# MSP430F5529 register map
Vendor: msp430gen; File version: VERGEN_IDEMPOTENT_OUTPUT
Registers are 8-bit, read-write, reset 0x0 unless marked. A register's access mark holds for its fields unless they carry their own. Offsets are from the block's base; [hi:lo] are bit positions; {n}, {i} and the like mark numbered series.

## USCI_A0_SPI_MODE
Base 0x000005C0
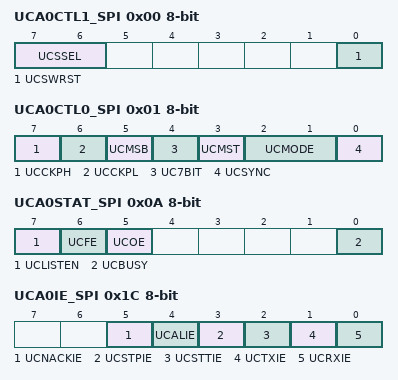
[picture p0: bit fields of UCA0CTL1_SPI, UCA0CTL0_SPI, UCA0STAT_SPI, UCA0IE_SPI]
0x00 UCA0CTL1_SPI — USCI A0 Control Register 1
  [7:6] UCSSEL — USCI 1 Clock Source Select 1
    {v}=USCI 0 Clock Source: {v} (v=0..3)
  [0] UCSWRST — USCI Software Reset
0x01 UCA0CTL0_SPI — USCI A0 Control Register 0
  [7] UCCKPH — Sync. Mode: Clock Phase
  [6] UCCKPL — Sync. Mode: Clock Polarity
  [5] UCMSB — Sync. Mode: MSB first 0:LSB / 1:MSB
  [4] UC7BIT — Sync. Mode: Data Bits 0:8-bits / 1:7-bits
  [3] UCMST — Sync. Mode: Master Select
  [2:1] UCMODE — Sync. Mode: USCI Mode 1
    {v}=Sync. Mode: USCI Mode: {v} (v=0..3)
  [0] UCSYNC — Sync-Mode 0:UART-Mode / 1:SPI-Mode
0x06 UCA0BR0_SPI — USCI A0 Baud Rate 0
0x07 UCA0BR1_SPI — USCI A0 Baud Rate 1
0x08 UCA0MCTL_SPI — USCI A0 Modulation Control
0x0A UCA0STAT_SPI — USCI A0 Status Register
  [7] UCLISTEN — USCI Listen mode
  [6] UCFE — USCI Frame Error Flag
  [5] UCOE — USCI Overrun Error Flag
  [0] UCBUSY — USCI Busy Flag
0x0C UCA0RXBUF_SPI — USCI A0 Receive Buffer
0x0E UCA0TXBUF_SPI — USCI A0 Transmit Buffer
0x1C UCA0IE_SPI — USCI A0 Interrupt Enable Register
  [5] UCNACKIE — NACK Condition interrupt enable
  [4] UCALIE — Arbitration Lost interrupt enable
  [3] UCSTPIE — STOP Condition interrupt enable
  [2] UCSTTIE — START Condition interrupt enable
  [1] UCTXIE — USCI Transmit Interrupt Enable
  [0] UCRXIE — USCI Receive Interrupt Enable
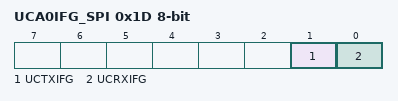
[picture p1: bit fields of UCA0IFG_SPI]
0x1D UCA0IFG_SPI — USCI A0 Interrupt Flags Register
  [1] UCTXIFG — USCI Transmit Interrupt Flag
  [0] UCRXIFG — USCI Receive Interrupt Flag
0x1E UCA0IV_SPI 16-bit — USCI A0 Interrupt Vector Register

## USCI_B0_I2C_MODE
Base 0x000005E0
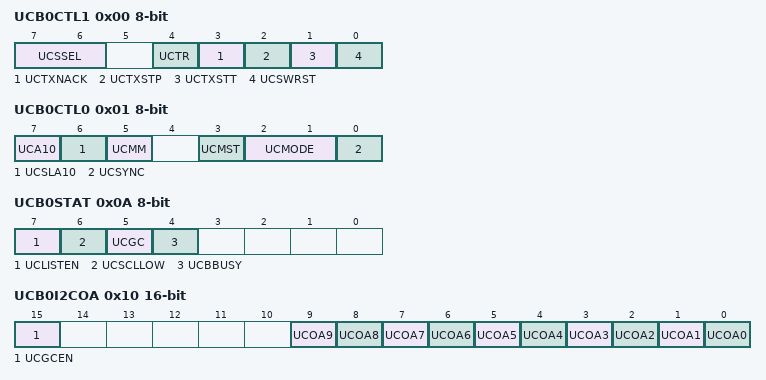
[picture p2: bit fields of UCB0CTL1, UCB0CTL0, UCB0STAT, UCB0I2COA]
0x00 UCB0CTL1 — USCI B0 Control Register 1
  [7:6] UCSSEL — USCI 1 Clock Source Select 1
    {v}=USCI 0 Clock Source: {v} (v=0..3)
  [4] UCTR — Transmit/Receive Select/Flag
  [3] UCTXNACK — Transmit NACK
  [2] UCTXSTP — Transmit STOP
  [1] UCTXSTT — Transmit START
  [0] UCSWRST — USCI Software Reset
0x01 UCB0CTL0 — USCI B0 Control Register 0
  [7] UCA10 — 10-bit Address Mode
  [6] UCSLA10 — 10-bit Slave Address Mode
  [5] UCMM — Multi-Master Environment
  [3] UCMST — Sync. Mode: Master Select
  [2:1] UCMODE — Sync. Mode: USCI Mode 1
    {v}=Sync. Mode: USCI Mode: {v} (v=0..3)
  [0] UCSYNC — Sync-Mode 0:UART-Mode / 1:SPI-Mode
0x06 UCB0BR0 — USCI B0 Baud Rate 0
0x07 UCB0BR1 — USCI B0 Baud Rate 1
0x0A UCB0STAT — USCI B0 Status Register
  [7] UCLISTEN — USCI Listen mode
  [6] UCSCLLOW — SCL low
  [5] UCGC — General Call address received Flag
  [4] UCBBUSY — Bus Busy Flag
0x0C UCB0RXBUF — USCI B0 Receive Buffer
0x0E UCB0TXBUF — USCI B0 Transmit Buffer
0x10 UCB0I2COA 16-bit — USCI B0 I2C Own Address
  [15] UCGCEN — I2C General Call enable
  [n] UCOA{n} (n=0..9) — I2C Own Address {n}
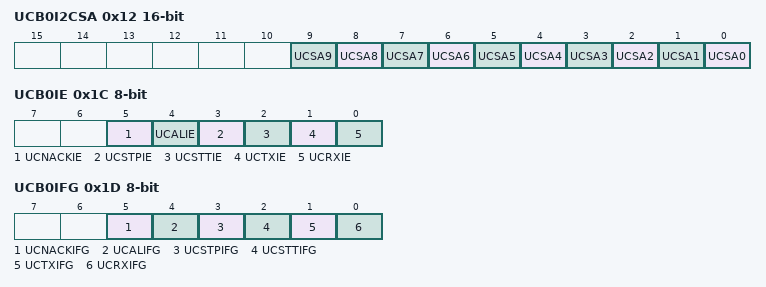
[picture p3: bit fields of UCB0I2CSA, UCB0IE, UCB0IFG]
0x12 UCB0I2CSA 16-bit — USCI B0 I2C Slave Address
  [n] UCSA{n} (n=0..9) — I2C Slave Address {n}
0x1C UCB0IE — USCI B0 Interrupt Enable Register
  [5] UCNACKIE — NACK Condition interrupt enable
  [4] UCALIE — Arbitration Lost interrupt enable
  [3] UCSTPIE — STOP Condition interrupt enable
  [2] UCSTTIE — START Condition interrupt enable
  [1] UCTXIE — USCI Transmit Interrupt Enable
  [0] UCRXIE — USCI Receive Interrupt Enable
0x1D UCB0IFG — USCI B0 Interrupt Flags Register
  [5] UCNACKIFG — NAK Condition interrupt Flag
  [4] UCALIFG — Arbitration Lost interrupt Flag
  [3] UCSTPIFG — STOP Condition interrupt Flag
  [2] UCSTTIFG — START Condition interrupt Flag
  [1] UCTXIFG — USCI Transmit Interrupt Flag
  [0] UCRXIFG — USCI Receive Interrupt Flag
0x1E UCB0IV 16-bit — USCI B0 Interrupt Vector Register

## USCI_B0_SPI_MODE
Base 0x000005E0
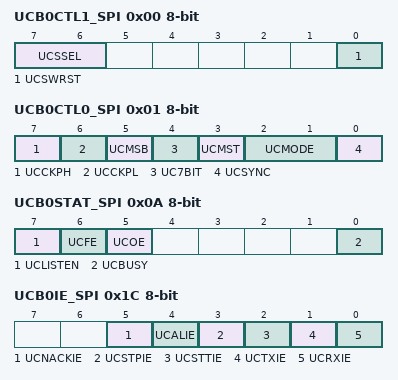
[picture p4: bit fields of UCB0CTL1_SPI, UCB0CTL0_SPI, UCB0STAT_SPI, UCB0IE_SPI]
0x00 UCB0CTL1_SPI — USCI B0 Control Register 1
  [7:6] UCSSEL — USCI 1 Clock Source Select 1
    {v}=USCI 0 Clock Source: {v} (v=0..3)
  [0] UCSWRST — USCI Software Reset
0x01 UCB0CTL0_SPI — USCI B0 Control Register 0
  [7] UCCKPH — Sync. Mode: Clock Phase
  [6] UCCKPL — Sync. Mode: Clock Polarity
  [5] UCMSB — Sync. Mode: MSB first 0:LSB / 1:MSB
  [4] UC7BIT — Sync. Mode: Data Bits 0:8-bits / 1:7-bits
  [3] UCMST — Sync. Mode: Master Select
  [2:1] UCMODE — Sync. Mode: USCI Mode 1
    {v}=Sync. Mode: USCI Mode: {v} (v=0..3)
  [0] UCSYNC — Sync-Mode 0:UART-Mode / 1:SPI-Mode
0x06 UCB0BR0_SPI — USCI B0 Baud Rate 0
0x07 UCB0BR1_SPI — USCI B0 Baud Rate 1
0x0A UCB0STAT_SPI — USCI B0 Status Register
  [7] UCLISTEN — USCI Listen mode
  [6] UCFE — USCI Frame Error Flag
  [5] UCOE — USCI Overrun Error Flag
  [0] UCBUSY — USCI Busy Flag
0x0C UCB0RXBUF_SPI — USCI B0 Receive Buffer
0x0E UCB0TXBUF_SPI — USCI B0 Transmit Buffer
0x1C UCB0IE_SPI — USCI B0 Interrupt Enable Register
  [5] UCNACKIE — NACK Condition interrupt enable
  [4] UCALIE — Arbitration Lost interrupt enable
  [3] UCSTPIE — STOP Condition interrupt enable
  [2] UCSTTIE — START Condition interrupt enable
  [1] UCTXIE — USCI Transmit Interrupt Enable
  [0] UCRXIE — USCI Receive Interrupt Enable
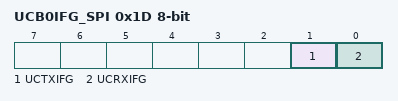
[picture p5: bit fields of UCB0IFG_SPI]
0x1D UCB0IFG_SPI — USCI B0 Interrupt Flags Register
  [1] UCTXIFG — USCI Transmit Interrupt Flag
  [0] UCRXIFG — USCI Receive Interrupt Flag
0x1E UCB0IV_SPI 16-bit — USCI B0 Interrupt Vector Register
